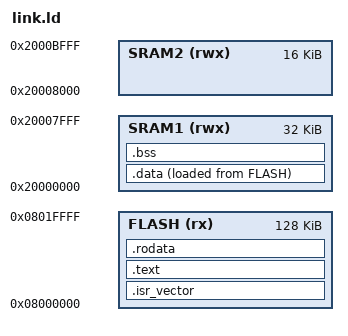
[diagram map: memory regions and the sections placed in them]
/* STM32WLE5CBU6 Linker Script */
MEMORY
{
    FLASH (rx)  : ORIGIN = 0x08000000, LENGTH = 128K
    SRAM1 (rwx) : ORIGIN = 0x20000000, LENGTH = 32K
    SRAM2 (rwx) : ORIGIN = 0x20008000, LENGTH = 16K
}

_estack = ORIGIN(SRAM1) + LENGTH(SRAM1);

SECTIONS
{
    .isr_vector :
    {
        . = ALIGN(4);
        KEEP(*(.isr_vector))
        . = ALIGN(4);
    } >FLASH

    .text :
    {
        . = ALIGN(4);
        *(.text)
        *(.text*)
        . = ALIGN(4);
    } >FLASH

    .rodata :
    {
        . = ALIGN(4);
        *(.rodata)
        *(.rodata*)
        . = ALIGN(4);
    } >FLASH

    .data :
    {
        . = ALIGN(4);
        _sdata = .;
        *(.data)
        *(.data*)
        . = ALIGN(4);
        _edata = .;
    } >SRAM1 AT> FLASH
    _sidata = LOADADDR(.data);

    .bss :
    {
        . = ALIGN(4);
        _sbss = .;
        *(.bss)
        *(.bss*)
        *(COMMON)
        . = ALIGN(4);
        _ebss = .;
    } >SRAM1
}
